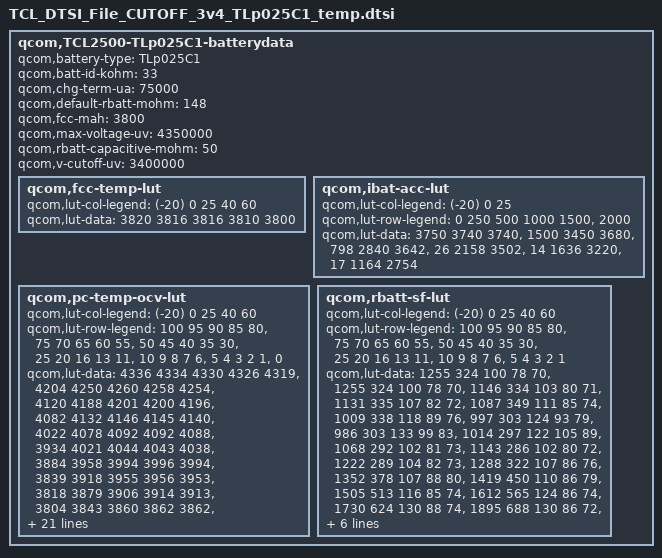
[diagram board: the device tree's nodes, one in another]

qcom,TCL2500-TLp025C1-batterydata {
	qcom,battery-type = "TLp025C1";
	qcom,batt-id-kohm = <33>;
	qcom,chg-term-ua = <75000>;
	qcom,default-rbatt-mohm = <148>;
	qcom,fcc-mah = <3800>;
	qcom,max-voltage-uv = <4350000>;
	qcom,rbatt-capacitive-mohm = <50>;
	qcom,v-cutoff-uv = <3400000>;

	qcom,fcc-temp-lut {
		qcom,lut-col-legend = <(-20) 0 25 40 60>;
		qcom,lut-data = <3820 3816 3816 3810 3800>;
	};

	qcom,ibat-acc-lut {
		qcom,lut-col-legend = <(-20) 0 25>;
		qcom,lut-row-legend = <0 250 500 1000 1500>,
					<2000>;
		qcom,lut-data = <3750 3740 3740>,
				<1500 3450 3680>,
				<798 2840 3642>,
				<26 2158 3502>,
				<14 1636 3220>,
				<17 1164 2754>;
	};

	qcom,pc-temp-ocv-lut {
		qcom,lut-col-legend = <(-20) 0 25 40 60>;
		qcom,lut-row-legend = <100 95 90 85 80>,
					<75 70 65 60 55>,
					<50 45 40 35 30>,
					<25 20 16 13 11>,
					<10 9 8 7 6>,
					<5 4 3 2 1>,
					<0>;
		qcom,lut-data = <4336 4334 4330 4326 4319>,
				<4204 4250 4260 4258 4254>,
				<4120 4188 4201 4200 4196>,
				<4082 4132 4146 4145 4140>,
				<4022 4078 4092 4092 4088>,
				<3934 4021 4044 4043 4038>,
				<3884 3958 3994 3996 3994>,
				<3839 3918 3955 3956 3953>,
				<3818 3879 3906 3914 3913>,
				<3804 3843 3860 3862 3862>,
				<3790 3813 3832 3834 3832>,
				<3777 3791 3810 3811 3810>,
				<3762 3781 3792 3793 3792>,
				<3747 3772 3776 3777 3776>,
				<3732 3760 3766 3763 3758>,
				<3716 3744 3754 3748 3736>,
				<3698 3719 3734 3727 3716>,
				<3680 3700 3708 3702 3690>,
				<3662 3690 3684 3678 3668>,
				<3648 3683 3678 3673 3664>,
				<3640 3679 3676 3672 3662>,
				<3630 3674 3675 3671 3661>,
				<3616 3669 3672 3668 3659>,
				<3601 3662 3668 3665 3655>,
				<3582 3651 3661 3657 3644>,
				<3558 3630 3638 3632 3616>,
				<3523 3593 3592 3586 3568>,
				<3475 3536 3528 3524 3506>,
				<3398 3452 3442 3440 3420>,
				<3263 3318 3309 3308 3288>,
				<3000 3046 3010 3000 3000>;
	};

	qcom,rbatt-sf-lut {
		qcom,lut-col-legend = <(-20) 0 25 40 60>;
		qcom,lut-row-legend = <100 95 90 85 80>,
					<75 70 65 60 55>,
					<50 45 40 35 30>,
					<25 20 16 13 11>,
					<10 9 8 7 6>,
					<5 4 3 2 1>;
		qcom,lut-data = <1255 324 100 78 70>,
				<1255 324 100 78 70>,
				<1146 334 103 80 71>,
				<1131 335 107 82 72>,
				<1087 349 111 85 74>,
				<1009 338 118 89 76>,
				<997 303 124 93 79>,
				<986 303 133 99 83>,
				<1014 297 122 105 89>,
				<1068 292 102 81 73>,
				<1143 286 102 80 72>,
				<1222 289 104 82 73>,
				<1288 322 107 86 76>,
				<1352 378 107 88 80>,
				<1419 450 110 86 79>,
				<1505 513 116 85 74>,
				<1612 565 124 86 74>,
				<1730 624 130 88 74>,
				<1895 688 130 86 72>,
				<2053 722 133 89 74>,
				<2195 739 136 92 76>,
				<2450 775 142 95 79>,
				<2774 819 150 99 80>,
				<3211 867 160 103 82>,
				<3799 924 171 106 82>,
				<4619 986 174 103 80>,
				<5857 1059 179 103 80>,
				<7886 1170 199 108 82>,
				<11732 1393 235 120 89>,
				<23465 2734 353 178 122>;
	};
};
/* TEST_DB_ID=TEST_ID_NOT_SET */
